# RK3399-AP register map
File version: 1
CPU: CA7 r0p1, little endian, MPU, FPU, I-cache, D-cache, VTOR, 4 interrupt priority bits, 0 interrupts
Registers are 32-bit, read-write, reset 0x0 unless marked. A register's access mark holds for its fields unless they carry their own. Offsets are from the block's base; [hi:lo] are bit positions; {n}, {i} and the like mark numbered series; 'fields as' and 'values as' point back to an identical list.

## PMUGRF
Base 0xFF320000
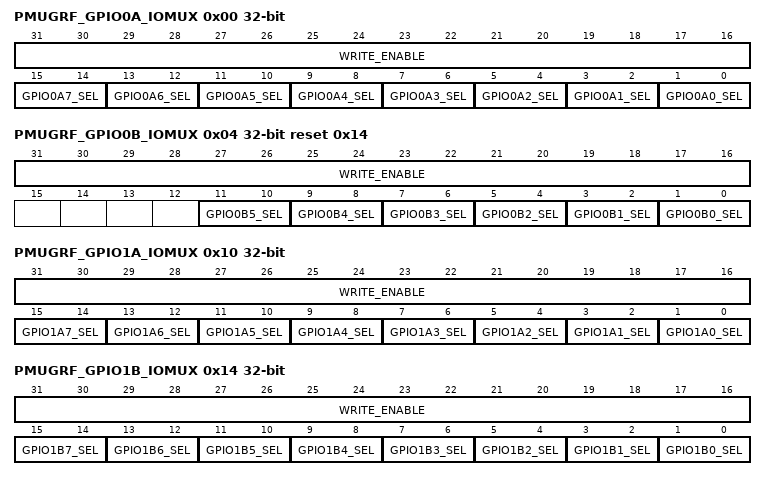
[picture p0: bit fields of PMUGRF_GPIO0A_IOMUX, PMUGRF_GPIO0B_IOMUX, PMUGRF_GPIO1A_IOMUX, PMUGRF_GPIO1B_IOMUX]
0x00 PMUGRF_GPIO0A_IOMUX — GPIO0A iomux control
  [31:16] WRITE_ENABLE — bit0~15 write enable When bit 16=1, bit 0 can be written by software . When bit 16=0, bit 0 cannot be written by software; When bit 17=1, bit 1 can be written by software . When bit 17=0, bit 1 cannot be written by software; ...... When bit 31=1, bit 15 can be written by software . When bit 31=0, bit 15 cannot be written by software;
  [15:14] GPIO0A7_SEL — GPIO0A[7] iomux select 2\'b00: gpio 2\'b01: sdmmc_dectn 2\'b10: pmu_debug5 2\'b11: reserved
  [13:12] GPIO0A6_SEL — GPIO0A[6] iomux select 2\'b00: gpio 2\'b01: pwm_3a 2\'b10: pmu_debug4 2\'b11: reserved
  [11:10] GPIO0A5_SEL — GPIO0A[5] iomux select 2\'b00: gpio 2\'b01: emmc_pwren 2\'b10: pmu_debug3 2\'b11: reserved
  [9:8] GPIO0A4_SEL — GPIO0A[4] iomux select 2\'b00: gpio 2\'b01: sdio_intn 2\'b10: pmu_debug2 2\'b11: reserved
  [7:6] GPIO0A3_SEL — GPIO0A[3] iomux select 2\'b00: gpio 2\'b01: sdio_wrprt 2\'b10: pmu_debug1 2\'b11: reserved
  [5:4] GPIO0A2_SEL — GPIO0A[2] iomux select 2\'b00: gpio 2\'b01: wifi_26m 2\'b10: pmu_debug0 2\'b11: reserved
  [3:2] GPIO0A1_SEL — GPIO0A[1] iomux select 2\'b00: gpio 2\'b01: ddrio_pwroff 2\'b10: tcpd_ccdben 2\'b11: reserved
  [1:0] GPIO0A0_SEL — GPIO0A[0] iomux select 2\'b00: gpio 2\'b01: test_clkout0 2\'b10: clk_32k 2\'b11: reserved
0x04 PMUGRF_GPIO0B_IOMUX reset 0x14 — GPIO0B iomux control
  [31:16] WRITE_ENABLE — bit0~15 write enable When bit 16=1, bit 0 can be written by software . When bit 16=0, bit 0 cannot be written by software; When bit 17=1, bit 1 can be written by software . When bit 17=0, bit 1 cannot be written by software; ...... When bit 31=1, bit 15 can be written by software . When bit 31=0, bit 15 cannot be written by software;
  [11:10] GPIO0B5_SEL — GPIO0B[5] iomux select 2\'b00: gpio 2\'b01: tcpd_vbusfdis 2\'b10: tcpdusb2_vbussource3 2\'b11: reserved
  [9:8] GPIO0B4_SEL — GPIO0B4] iomux select 2\'b00: gpio 2\'b01: tcpd_vbusbdis 2\'b10: reserved 2\'b11: reserved
  [7:6] GPIO0B3_SEL — GPIO0B[3] iomux select 2\'b00: gpio 2\'b01: reserved 2\'b10: reserved 2\'b11: reserved
  [5:4] GPIO0B2_SEL — GPIO0B[2] iomux select 2\'b00: gpio 2\'b01: reserved 2\'b10: reserved 2\'b11: reserved
  [3:2] GPIO0B1_SEL — GPIO0B[1] iomux select 2\'b00: gpio 2\'b01: pmu1830_volsel 2\'b10: reserved 2\'b11: reserved
  [1:0] GPIO0B0_SEL — GPIO0B[0] iomux select 2\'b00: gpio 2\'b01: sdmmc_wrprt 2\'b10: pmum0_wfi 2\'b11: test_clkout2
0x10 PMUGRF_GPIO1A_IOMUX — GPIO1A iomux control
  [31:16] WRITE_ENABLE — bit0~15 write enable When bit 16=1, bit 0 can be written by software . When bit 16=0, bit 0 cannot be written by software; When bit 17=1, bit 1 can be written by software . When bit 17=0, bit 1 cannot be written by software; ...... When bit 31=1, bit 15 can be written by software . When bit 31=0, bit 15 cannot be written by software;
  [15:14] GPIO1A7_SEL — GPIO1A[7] iomux select 2\'b00: gpio 2\'b01: uart4m0_sin 2\'b10: spi1ec_rxd 2\'b11: reserved
  [13:12] GPIO1A6_SEL — GPIO1A[6] iomux select 2\'b00: gpio 2\'b01: tsadc_int 2\'b10: reserved 2\'b11: reserved
  [11:10] GPIO1A5_SEL — GPIO1A[5] iomux select 2\'b00: gpio 2\'b01: ap_pwroff 2\'b10: reserved 2\'b11: reserved
  [9:8] GPIO1A4_SEL — GPIO1A[4] iomux select 2\'b00: gpio 2\'b01: isp0_prelighttrig 2\'b10: isp1_prelighttrig 2\'b11: reserved
  [7:6] GPIO1A3_SEL — GPIO1A[3] iomux select 2\'b00: gpio 2\'b01: isp0_flashtrigout 2\'b10: isp1_flashtrigout 2\'b11: reserved
  [5:4] GPIO1A2_SEL — GPIO1A[2] iomux select 2\'b00: gpio 2\'b01: isp0_flashtrigin 2\'b10: isp1_flashtrigin 2\'b11: tcpd_cc1vconn
  [3:2] GPIO1A1_SEL — GPIO1A[1] iomux select 2\'b00: gpio 2\'b01: isp0_shuttertrig 2\'b10: isp1_shuttertrig 2\'b11: tcpd_cc0vconn
  [1:0] GPIO1A0_SEL — GPIO1A[0] iomux select 2\'b00: gpio 2\'b01: isp0_shutteren 2\'b10: isp1_shutteren 2\'b11: tcpd_vbussink
0x14 PMUGRF_GPIO1B_IOMUX access per field — GPIO1B iomux control
  [31:16] WRITE_ENABLE wo — bit0~15 write enable When bit 16=1, bit 0 can be written by software . When bit 16=0, bit 0 cannot be written by software; When bit 17=1, bit 1 can be written by software . When bit 17=0, bit 1 cannot be written by software; ...... When bit 31=1, bit 15 can be written by software . When bit 31=0, bit 15 cannot be written by software;
  [15:14] GPIO1B7_SEL rw — GPIO1B[7] iomux select 2\'b00: gpio 2\'b01: spi3pmu_rxd 2\'b10: i2c0pmu_scl 2\'b11: reserved
  [13:12] GPIO1B6_SEL rw — GPIO1B[6] iomux select 2\'b00: gpio 2\'b01: pwm_3b 2\'b10: reserved 2\'b11: reserved
  [11:10] GPIO1B5_SEL rw — GPIO1B[5] iomux select 2\'b00: gpio 2\'b01: reserved 2\'b10: reserved 2\'b11: reserved
  [9:8] GPIO1B4_SEL rw — GPIO1B[4] iomux select 2\'b00: gpio 2\'b01: i2c4sensor_scl 2\'b10: reserved 2\'b11: reserved
  [7:6] GPIO1B3_SEL rw — GPIO1B[3] iomux select 2\'b00: gpio 2\'b01: i2c4sensor_sda 2\'b10: reserved 2\'b11: reserved
  [5:4] GPIO1B2_SEL rw — GPIO1B[2] iomux select 2\'b00: gpio 2\'b01: pmum0jtag_tms 2\'b10: spi1ec_csn0 2\'b11: reserved
  [3:2] GPIO1B1_SEL rw — GPIO1B[1] iomux select 2\'b00: gpio 2\'b01: pmum0jtag_tck 2\'b10: spi1ec_clk 2\'b11: reserved
  [1:0] GPIO1B0_SEL rw — GPIO1B[0] iomux select 2\'b00: gpio 2\'b01: uart4m0_sout 2\'b10: spi1ec_txd 2\'b11: reserved
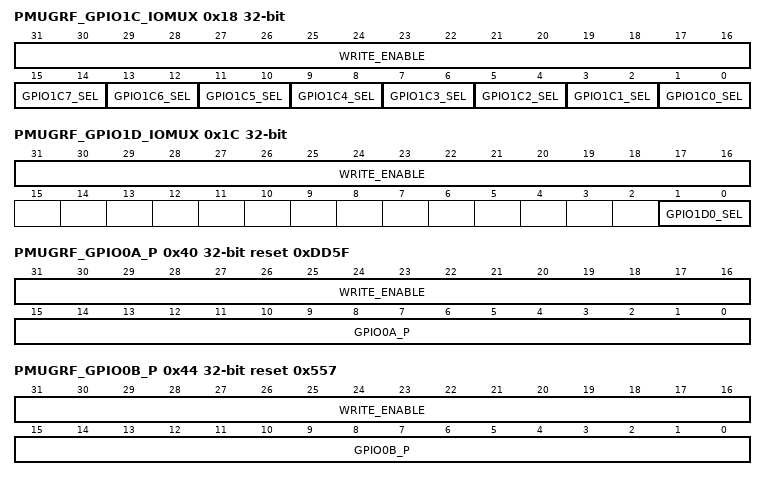
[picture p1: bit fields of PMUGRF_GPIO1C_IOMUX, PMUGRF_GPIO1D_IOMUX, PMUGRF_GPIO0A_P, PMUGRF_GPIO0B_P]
0x18 PMUGRF_GPIO1C_IOMUX access per field — GPIO1C iomux control
  [31:16] WRITE_ENABLE wo — bit0~15 write enable When bit 16=1, bit 0 can be written by software . When bit 16=0, bit 0 cannot be written by software; When bit 17=1, bit 1 can be written by software . When bit 17=0, bit 1 cannot be written by software; ...... When bit 31=1, bit 15 can be written by software . When bit 31=0, bit 15 cannot be written by software;
  [15:14] GPIO1C7_SEL rw — GPIO1C[7] iomux select 2\'b00: gpio 2\'b01: tcpdusb2_vbussource1 2\'b10: reserved 2\'b11: reserved
  [13:12] GPIO1C6_SEL rw — GPIO1C[6] iomux select 2\'b00: gpio 2\'b01: tcpdusb2_vbussource0 2\'b10: reserved 2\'b11: reserved
  [11:10] GPIO1C5_SEL rw — GPIO1C[5] iomux select 2\'b00: gpio 2\'b01: i2c8dcdc_scl 2\'b10: reserved 2\'b11: reserved
  [9:8] GPIO1C4_SEL rw — GPIO1C[4] iomux select 2\'b00: gpio 2\'b01: i2c8dcdc_sda 2\'b10: reserved 2\'b11: reserved
  [7:6] GPIO1C3_SEL rw — GPIO1C[3] iomux select 2\'b00: gpio 2\'b01: pwm_2 2\'b10: reserved 2\'b11: reserved
  [5:4] GPIO1C2_SEL rw — GPIO1C[2] iomux select 2\'b00: gpio 2\'b01: spi3pmu_csn0 2\'b10: reserved 2\'b11: reserved
  [3:2] GPIO1C1_SEL rw — GPIO1C[1] iomux select 2\'b00: gpio 2\'b01: spi3pmu_clk 2\'b10: reserved 2\'b11: reserved
  [1:0] GPIO1C0_SEL rw — GPIO1C[0] iomux select 2\'b00: gpio 2\'b01: spi3pmu_txd 2\'b10: i2c0pmu_scl 2\'b11: reserved
0x1C PMUGRF_GPIO1D_IOMUX access per field — GPIO1D iomux control
  [31:16] WRITE_ENABLE wo — bit0~15 write enable When bit 16=1, bit 0 can be written by software . When bit 16=0, bit 0 cannot be written by software; When bit 17=1, bit 1 can be written by software . When bit 17=0, bit 1 cannot be written by software; ...... When bit 31=1, bit 15 can be written by software . When bit 31=0, bit 15 cannot be written by software;
  [1:0] GPIO1D0_SEL rw — GPIO1D[0] iomux select 2\'b00: gpio 2\'b01: tcpdusb2_vbussource2 2\'b10: reserved 2\'b11: reserved
0x40 PMUGRF_GPIO0A_P access per field reset 0xDD5F — GPIO0A PU/PD control
  [31:16] WRITE_ENABLE wo — bit0~15 write enable When bit 16=1, bit 0 can be written by software . When bit 16=0, bit 0 cannot be written by software; When bit 17=1, bit 1 can be written by software . When bit 17=0, bit 1 cannot be written by software; ...... When bit 31=1, bit 15 can be written by software . When bit 31=0, bit 15 cannot be written by software;
  [15:0] GPIO0A_P rw — GPIO0A PE/PS programmation section, every GPIO bit corresponding to 2bits[PS:PE] 2\'b00: Z(Noraml operaton); 2\'b11: weak 1(pull-up); 2\'b01: weak 0(pull-down); 2\'b10: Z(Noraml operaton);
0x44 PMUGRF_GPIO0B_P access per field reset 0x557 — GPIO0B PU/PD control
  [31:16] WRITE_ENABLE wo — bit0~15 write enable When bit 16=1, bit 0 can be written by software . When bit 16=0, bit 0 cannot be written by software; When bit 17=1, bit 1 can be written by software . When bit 17=0, bit 1 cannot be written by software; ...... When bit 31=1, bit 15 can be written by software . When bit 31=0, bit 15 cannot be written by software;
  [15:0] GPIO0B_P rw — GPIO0A PE/PS programmation section, every GPIO bit corresponding to 2bits[PS:PE] 2\'b00: Z(Noraml operaton); 2\'b11: weak 1(pull-up); 2\'b01: weak 0(pull-down); 2\'b10: Z(Noraml operaton);
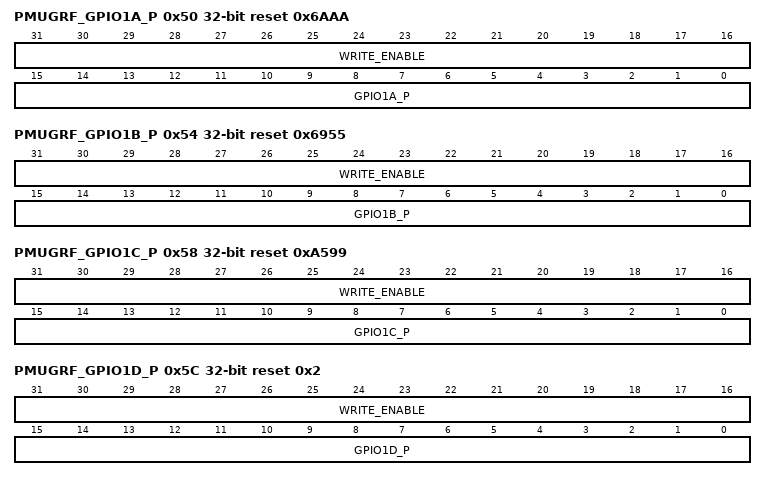
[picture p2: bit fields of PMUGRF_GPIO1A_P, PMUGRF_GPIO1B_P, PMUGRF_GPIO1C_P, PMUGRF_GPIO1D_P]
0x50 PMUGRF_GPIO1A_P access per field reset 0x6AAA — GPIO1A PU/PD control
  [31:16] WRITE_ENABLE wo — bit0~15 write enable When bit 16=1, bit 0 can be written by software . When bit 16=0, bit 0 cannot be written by software; When bit 17=1, bit 1 can be written by software . When bit 17=0, bit 1 cannot be written by software; ...... When bit 31=1, bit 15 can be written by software . When bit 31=0, bit 15 cannot be written by software;
  [15:0] GPIO1A_P rw — GPIO1A PU/PD programmation section, every GPIO bit corresponding to 2bits 2\'b00: Z(Noraml operaton); 2\'b01: weak 1(pull-up); 2\'b10: weak 0(pull-down); 2\'b11: Repeater(Bus keeper)
0x54 PMUGRF_GPIO1B_P access per field reset 0x6955 — GPIO1B PU/PD control
  [31:16] WRITE_ENABLE wo — bit0~15 write enable When bit 16=1, bit 0 can be written by software . When bit 16=0, bit 0 cannot be written by software; When bit 17=1, bit 1 can be written by software . When bit 17=0, bit 1 cannot be written by software; ...... When bit 31=1, bit 15 can be written by software . When bit 31=0, bit 15 cannot be written by software;
  [15:0] GPIO1B_P rw — GPIO1B PU/PD programmation section, every GPIO bit corresponding to 2bits 2\'b00: Z(Noraml operaton); 2\'b01: weak 1(pull-up); 2\'b10: weak 0(pull-down); 2\'b11: Repeater(Bus keeper)
0x58 PMUGRF_GPIO1C_P access per field reset 0xA599 — GPIO1C PU/PD control
  [31:16] WRITE_ENABLE wo — bit0~15 write enable When bit 16=1, bit 0 can be written by software . When bit 16=0, bit 0 cannot be written by software; When bit 17=1, bit 1 can be written by software . When bit 17=0, bit 1 cannot be written by software; ...... When bit 31=1, bit 15 can be written by software . When bit 31=0, bit 15 cannot be written by software;
  [15:0] GPIO1C_P rw — GPIO1C PU/PD programmation section, every GPIO bit corresponding to 2bits 2\'b00: Z(Noraml operaton); 2\'b01: weak 1(pull-up); 2\'b10: weak 0(pull-down); 2\'b11: Repeater(Bus keeper)
0x5C PMUGRF_GPIO1D_P access per field reset 0x2 — GPIO0D PU/PD control
  [31:16] WRITE_ENABLE wo — bit0~15 write enable When bit 16=1, bit 0 can be written by software . When bit 16=0, bit 0 cannot be written by software; When bit 17=1, bit 1 can be written by software . When bit 17=0, bit 1 cannot be written by software; ...... When bit 31=1, bit 15 can be written by software . When bit 31=0, bit 15 cannot be written by software;
  [15:0] GPIO1D_P rw — GPIO1D PU/PD programmation section, every GPIO bit corresponding to 2bits 2\'b00: Z(Noraml operaton); 2\'b01: weak 1(pull-up); 2\'b10: weak 0(pull-down); 2\'b11: Repeater(Bus keeper)
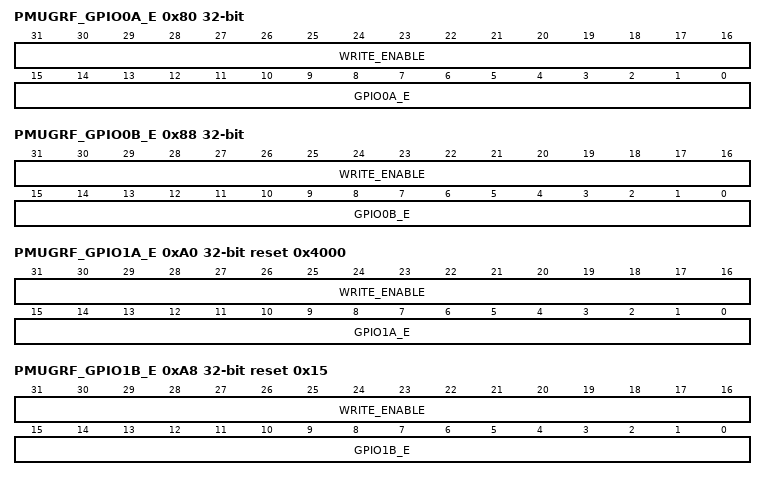
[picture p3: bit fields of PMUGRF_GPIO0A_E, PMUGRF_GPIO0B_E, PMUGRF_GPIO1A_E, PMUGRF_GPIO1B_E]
0x80 PMUGRF_GPIO0A_E access per field — GPIO0A drive strength control
  [31:16] WRITE_ENABLE wo — bit0~15 write enable When bit 16=1, bit 0 can be written by software . When bit 16=0, bit 0 cannot be written by software; When bit 17=1, bit 1 can be written by software . When bit 17=0, bit 1 cannot be written by software; ...... When bit 31=1, bit 15 can be written by software . When bit 31=0, bit 15 cannot be written by software;
  [15:0] GPIO0A_E rw — GPIO0A drive strength control, every GPIO bit corresponding to 2bits 2\'b00: 2mA 2\'b01: 4mA 2\'b10: 8mA 2\'b11: 12mA
0x88 PMUGRF_GPIO0B_E access per field — GPIO0D drive strength control
  [31:16] WRITE_ENABLE wo — bit0~15 write enable When bit 16=1, bit 0 can be written by software . When bit 16=0, bit 0 cannot be written by software; When bit 17=1, bit 1 can be written by software . When bit 17=0, bit 1 cannot be written by software; ...... When bit 31=1, bit 15 can be written by software . When bit 31=0, bit 15 cannot be written by software;
  [15:0] GPIO0B_E rw — GPIO0B drive strength control, every GPIO bit corresponding to 2bits 2\'b00: 2mA 2\'b01: 4mA 2\'b10: 8mA 2\'b11: 12mA
0xA0 PMUGRF_GPIO1A_E access per field reset 0x4000 — GPIO1A drive strength control
  [31:16] WRITE_ENABLE wo — bit0~15 write enable When bit 16=1, bit 0 can be written by software . When bit 16=0, bit 0 cannot be written by software; When bit 17=1, bit 1 can be written by software . When bit 17=0, bit 1 cannot be written by software; ...... When bit 31=1, bit 15 can be written by software . When bit 31=0, bit 15 cannot be written by software;
  [15:0] GPIO1A_E rw — GPIO1A drive strength control, every GPIO bit corresponding to 2bits 2\'b00: 2mA 2\'b01: 4mA 2\'b10: 8mA 2\'b11: 12mA
0xA8 PMUGRF_GPIO1B_E access per field reset 0x15 — GPIO1D drive strength control
  [31:16] WRITE_ENABLE wo — bit0~15 write enable When bit 16=1, bit 0 can be written by software . When bit 16=0, bit 0 cannot be written by software; When bit 17=1, bit 1 can be written by software . When bit 17=0, bit 1 cannot be written by software; ...... When bit 31=1, bit 15 can be written by software . When bit 31=0, bit 15 cannot be written by software;
  [15:0] GPIO1B_E rw — GPIO1B drive strength control, every GPIO bit corresponding to 2bits 2\'b00: 2mA 2\'b01: 4mA 2\'b10: 8mA 2\'b11: 12mA
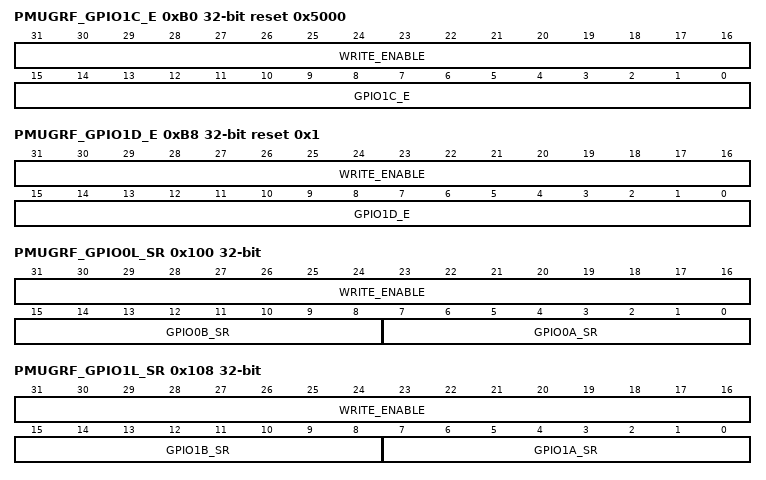
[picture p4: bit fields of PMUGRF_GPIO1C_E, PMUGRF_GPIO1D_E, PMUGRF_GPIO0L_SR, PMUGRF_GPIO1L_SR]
0xB0 PMUGRF_GPIO1C_E access per field reset 0x5000 — GPIO1C drive strength control
  [31:16] WRITE_ENABLE wo — bit0~15 write enable When bit 16=1, bit 0 can be written by software . When bit 16=0, bit 0 cannot be written by software; When bit 17=1, bit 1 can be written by software . When bit 17=0, bit 1 cannot be written by software; ...... When bit 31=1, bit 15 can be written by software . When bit 31=0, bit 15 cannot be written by software;
  [15:0] GPIO1C_E rw — GPIO1C drive strength control, every GPIO bit corresponding to 2bits 2\'b00: 2mA 2\'b01: 4mA 2\'b10: 8mA 2\'b11: 12mA
0xB8 PMUGRF_GPIO1D_E access per field reset 0x1 — GPIO1D drive strength control
  [31:16] WRITE_ENABLE wo — bit0~15 write enable When bit 16=1, bit 0 can be written by software . When bit 16=0, bit 0 cannot be written by software; When bit 17=1, bit 1 can be written by software . When bit 17=0, bit 1 cannot be written by software; ...... When bit 31=1, bit 15 can be written by software . When bit 31=0, bit 15 cannot be written by software;
  [15:0] GPIO1D_E rw — GPIO1D drive strength control, every GPIO bit corresponding to 2bits 2\'b00: 2mA 2\'b01: 4mA 2\'b10: 8mA 2\'b11: 12mA
0x100 PMUGRF_GPIO0L_SR access per field — GPIO0 A/B SR control
  [31:16] WRITE_ENABLE wo — bit0~15 write enable When bit 16=1, bit 0 can be written by software . When bit 16=0, bit 0 cannot be written by software; When bit 17=1, bit 1 can be written by software . When bit 17=0, bit 1 cannot be written by software; ...... When bit 31=1, bit 15 can be written by software . When bit 31=0, bit 15 cannot be written by software;
  [15:8] GPIO0B_SR rw — GPIO0B slew rate control for each bit 1\'b0: slow (half frequency) 1\'b1: fast
  [7:0] GPIO0A_SR rw — GPIO0A slew rate control for each bit 1\'b0: slow (half frequency) 1\'b1: fast
0x108 PMUGRF_GPIO1L_SR access per field — GPIO1 A/B SR control
  [31:16] WRITE_ENABLE wo — bit0~15 write enable When bit 16=1, bit 0 can be written by software . When bit 16=0, bit 0 cannot be written by software; When bit 17=1, bit 1 can be written by software . When bit 17=0, bit 1 cannot be written by software; ...... When bit 31=1, bit 15 can be written by software . When bit 31=0, bit 15 cannot be written by software;
  [15:8] GPIO1B_SR rw — GPIO1B slew rate control for each bit 1\'b0: slow (half frequency) 1\'b1: fast
  [7:0] GPIO1A_SR rw — GPIO1A slew rate control for each bit 1\'b0: slow (half frequency) 1\'b1: fast
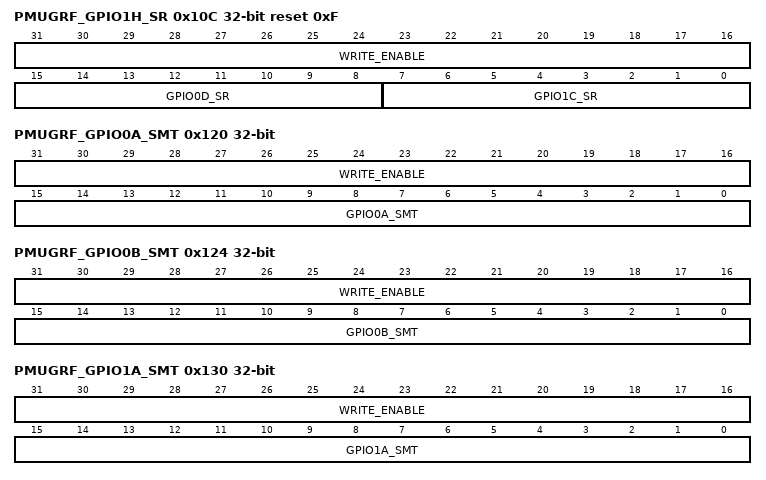
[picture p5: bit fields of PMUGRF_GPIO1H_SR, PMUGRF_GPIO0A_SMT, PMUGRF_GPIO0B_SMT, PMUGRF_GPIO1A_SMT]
0x10C PMUGRF_GPIO1H_SR access per field reset 0xF — GPIO1C/D SR control
  [31:16] WRITE_ENABLE wo — bit0~15 write enable When bit 16=1, bit 0 can be written by software . When bit 16=0, bit 0 cannot be written by software; When bit 17=1, bit 1 can be written by software . When bit 17=0, bit 1 cannot be written by software; ...... When bit 31=1, bit 15 can be written by software . When bit 31=0, bit 15 cannot be written by software;
  [15:8] GPIO0D_SR rw — GPIO0D slew rate control for each bit 1\'b0: slow (half frequency) 1\'b1: fast
  [7:0] GPIO1C_SR rw — GPIO1C slew rate control for each bit 1\'b0: slow (half frequency) 1\'b1: fast
0x120 PMUGRF_GPIO0A_SMT access per field — GPIO0A smit control
  [31:16] WRITE_ENABLE wo — bit0~15 write enable When bit 16=1, bit 0 can be written by software . When bit 16=0, bit 0 cannot be written by software; When bit 17=1, bit 1 can be written by software . When bit 17=0, bit 1 cannot be written by software; ...... When bit 31=1, bit 15 can be written by software . When bit 31=0, bit 15 cannot be written by software;
  [15:0] GPIO0A_SMT rw — GPIO0A drive strength control, every GPIO bit corresponding to 2bits 2\'b00: smit disable 2\'b01: smit enable 2\'b10: reserved 2\'b11: reserved
0x124 PMUGRF_GPIO0B_SMT access per field — GPIO0B smit control
  [31:16] WRITE_ENABLE wo — bit0~15 write enable When bit 16=1, bit 0 can be written by software . When bit 16=0, bit 0 cannot be written by software; When bit 17=1, bit 1 can be written by software . When bit 17=0, bit 1 cannot be written by software; ...... When bit 31=1, bit 15 can be written by software . When bit 31=0, bit 15 cannot be written by software;
  [15:0] GPIO0B_SMT rw — GPIO0B drive strength control, every GPIO bit corresponding to 2bits 2\'b00: smit disable 2\'b01: smit enable 2\'b10: reserved 2\'b11: reserved
0x130 PMUGRF_GPIO1A_SMT access per field — GPIO1A smit control
  [31:16] WRITE_ENABLE wo — bit0~15 write enable When bit 16=1, bit 0 can be written by software . When bit 16=0, bit 0 cannot be written by software; When bit 17=1, bit 1 can be written by software . When bit 17=0, bit 1 cannot be written by software; ...... When bit 31=1, bit 15 can be written by software . When bit 31=0, bit 15 cannot be written by software;
  [15:0] GPIO1A_SMT rw — GPIO1A drive strength control, every GPIO bit corresponding to 2bits 2\'b00: smit disable 2\'b01: smit enable 2\'b10: reserved 2\'b11: reserved
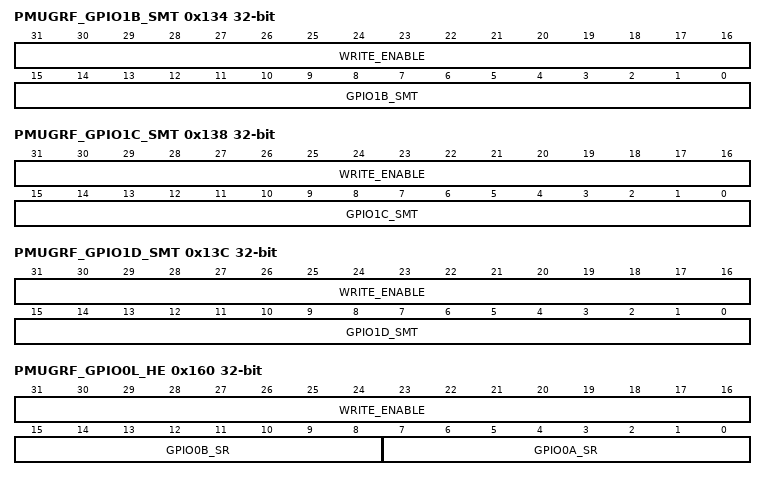
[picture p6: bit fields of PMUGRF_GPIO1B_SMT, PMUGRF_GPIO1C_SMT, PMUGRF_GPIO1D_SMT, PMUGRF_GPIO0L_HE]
0x134 PMUGRF_GPIO1B_SMT access per field — GPIO1B smit control
  [31:16] WRITE_ENABLE wo — bit0~15 write enable When bit 16=1, bit 0 can be written by software . When bit 16=0, bit 0 cannot be written by software; When bit 17=1, bit 1 can be written by software . When bit 17=0, bit 1 cannot be written by software; ...... When bit 31=1, bit 15 can be written by software . When bit 31=0, bit 15 cannot be written by software;
  [15:0] GPIO1B_SMT rw — GPIO1B drive strength control, every GPIO bit corresponding to 2bits 2\'b00: smit disable 2\'b01: smit enable 2\'b10: reserved 2\'b11: reserved
0x138 PMUGRF_GPIO1C_SMT access per field — GPIO1C smit control
  [31:16] WRITE_ENABLE wo — bit0~15 write enable When bit 16=1, bit 0 can be written by software . When bit 16=0, bit 0 cannot be written by software; When bit 17=1, bit 1 can be written by software . When bit 17=0, bit 1 cannot be written by software; ...... When bit 31=1, bit 15 can be written by software . When bit 31=0, bit 15 cannot be written by software;
  [15:0] GPIO1C_SMT rw — GPIO1C drive strength control, every GPIO bit corresponding to 2bits 2\'b00: smit disable 2\'b01: smit enable 2\'b10: reserved 2\'b11: reserved
0x13C PMUGRF_GPIO1D_SMT access per field — GPIO1D smit control
  [31:16] WRITE_ENABLE wo — bit0~15 write enable When bit 16=1, bit 0 can be written by software . When bit 16=0, bit 0 cannot be written by software; When bit 17=1, bit 1 can be written by software . When bit 17=0, bit 1 cannot be written by software; ...... When bit 31=1, bit 15 can be written by software . When bit 31=0, bit 15 cannot be written by software;
  [15:0] GPIO1D_SMT rw — GPIO1D drive strength control, every GPIO bit corresponding to 2bits 2\'b00: smit disable 2\'b01: smit enable 2\'b10: reserved 2\'b11: reserved
0x160 PMUGRF_GPIO0L_HE access per field — GPIO0 A/B HE control
  fields as PMUGRF_GPIO0L_SR
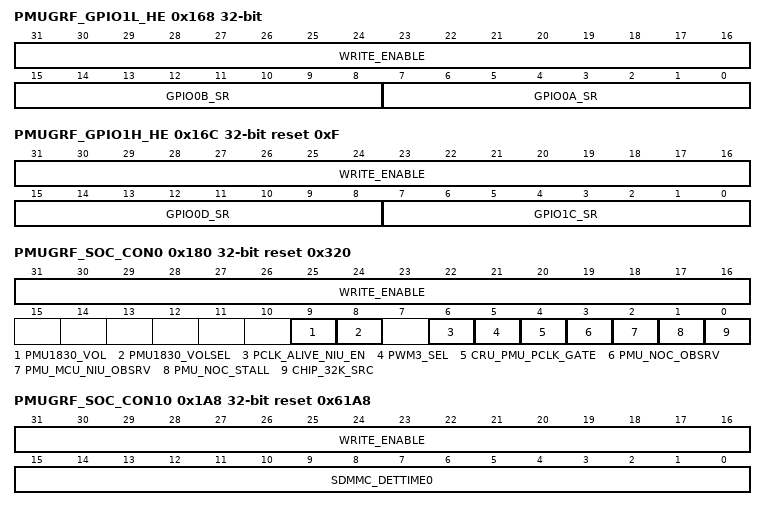
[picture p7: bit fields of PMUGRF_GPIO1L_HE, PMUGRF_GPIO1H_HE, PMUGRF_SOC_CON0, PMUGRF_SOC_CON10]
0x168 PMUGRF_GPIO1L_HE access per field — GPIO1 A/B HE control
  fields as PMUGRF_GPIO0L_SR
0x16C PMUGRF_GPIO1H_HE access per field reset 0xF — GPIO1C/D HE control
  fields as PMUGRF_GPIO1H_SR
0x180 PMUGRF_SOC_CON0 reset 0x320 — SoC control register 0
  [31:16] WRITE_ENABLE — bit0~15 write enable When bit 16=1, bit 0 can be written by software . When bit 16=0, bit 0 cannot be written by software; When bit 17=1, bit 1 can be written by software . When bit 17=0, bit 1 cannot be written by software; ...... When bit 31=1, bit 15 can be written by software . When bit 31=0, bit 15 cannot be written by software;
  [9] PMU1830_VOL — pmu IO 1.8v/3.0v select. 0: 3.0v ; 1: 1.8v ;
  [8] PMU1830_VOLSEL — pmu GPIO1 1.8v/3.0v control source select. 0: controlled by IO_GPIO0B1 ; 1: controlled by PMUGRF.SOC_CON0.pmu1830_vol
  [6] PCLK_ALIVE_NIU_EN — pd_alive pclk_niu gating. 1: gating ; 0: not gating .
  [5] PWM3_SEL — Use 2 optional IOs for pwm3. 0: pwm3a 1: pwm3b
  [4] CRU_PMU_PCLK_GATE — 1: gate clock ; 0: not gate .
  [3] PMU_NOC_OBSRV
  [2] PMU_MCU_NIU_OBSRV
  [1] PMU_NOC_STALL — When pmu noc meet illegal access, the noc will 0: error reponse 1: stall
  [0] CHIP_32K_SRC — chip 32K clock source select 0: from external 1: from internal, pvtm
0x1A8 PMUGRF_SOC_CON10 reset 0x61A8 — SoC control register 10
  [31:16] WRITE_ENABLE — bit0~15 write enable When bit 16=1, bit 0 can be written by software . When bit 16=0, bit 0 cannot be written by software; When bit 17=1, bit 1 can be written by software . When bit 17=0, bit 1 cannot be written by software; ...... When bit 31=1, bit 15 can be written by software . When bit 31=0, bit 15 cannot be written by software;
  [15:0] SDMMC_DETTIME0 — sdmmc_dettime[15:0]
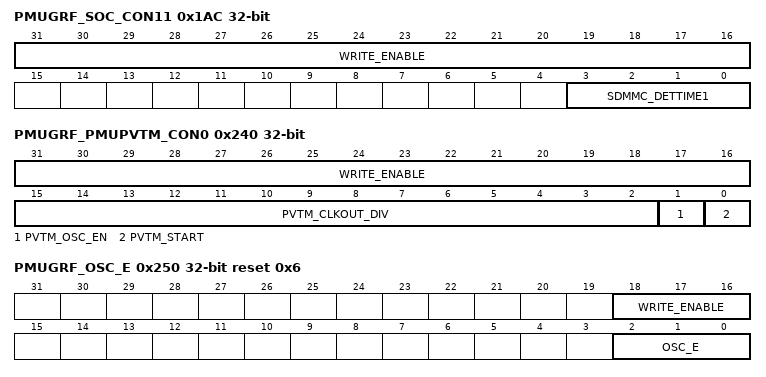
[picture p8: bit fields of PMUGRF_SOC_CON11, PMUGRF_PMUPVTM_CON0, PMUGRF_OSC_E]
0x1AC PMUGRF_SOC_CON11 — SoC control register 11
  [31:16] WRITE_ENABLE — bit0~15 write enable When bit 16=1, bit 0 can be written by software . When bit 16=0, bit 0 cannot be written by software; When bit 17=1, bit 1 can be written by software . When bit 17=0, bit 1 cannot be written by software; ...... When bit 31=1, bit 15 can be written by software . When bit 31=0, bit 15 cannot be written by software;
  [3:0] SDMMC_DETTIME1 — sdmmc_dettime[19:16]
0x240 PMUGRF_PMUPVTM_CON0 — pmu pvtm configuration register0
  [31:16] WRITE_ENABLE — When bit 16=1, bit 0 can be written by software . When bit 16=0, bit 0 cannot be written by software; When bit 17=1, bit 1 can be written by software . When bit 17=0, bit 1 cannot be written by software; ...... When bit 31=1, bit 15 can be written by software . When bit 31=0, bit 15 cannot be written by software;
  [15:2] PVTM_CLKOUT_DIV — clk_pvtm_out_div=clk_pvtm_out/pvtm_clko ut_div
  [1] PVTM_OSC_EN — pmu pvtm osc enable
  [0] PVTM_START — pmu pvtm start
0x244 PMUGRF_PMUPVTM_CON1 — pmu pvtm configuration register1
  [31:0] PVTM_CORE_CAL_CNT — pd_core pvtm calculator counter
0x248 PMUGRF_PMUPVTM_STATUS0 — pmu pvtm status register
  [0] PVTM_FREQ_DONE — pvtm frequency calculate done status
0x24C PMUGRF_PMUPVTM_STATUS1 — pmu pvtm status register
  [31:0] PVTM_FREQ_CNT — pvtm frequency count
0x250 PMUGRF_OSC_E reset 0x6 — OSC control register
  [18:16] WRITE_ENABLE — When bit 16=1, bit 0 can be written by software . When bit 16=0, bit 0 cannot be written by software; When bit 17=1, bit 1 can be written by software . When bit 17=0, bit 1 cannot be written by software; When bit 18=1, bit 2 can be written by software . When bit 18=0, bit 2 cannot be written by software;
  [2:0] OSC_E — 24M OSC drive strenth
{0x300+4i} PMUGRF_OS_REG{i} (i=0..3) — os register
  [31:0] OS_REG{i}
